AUTOSAR XML (schema 3-2-1)
package /heater/Blinker_swc
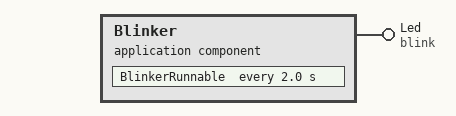
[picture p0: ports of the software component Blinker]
  application software component type Blinker
    provide port Led: unqueued-sender-com-spec{data-element=BlinkElement, alive-timeout=60.0}, provided-interface=blink
  internal behavior BlinkerBehavior: component=Blinker
    timing event TimingEvent: start-on-event=BlinkerRunnable, period=2.0
    runnable BlinkerRunnable: can-be-invoked-concurrently=true
      data write access BlinkerAccess: data-element=Led.BlinkElement
  swc implementation BlinkerImplementation: behavior=BlinkerBehavior
